AUTOSAR XML (schema 4-3-0)
standard types defined: UINT8, UINT16, UINT32, UINT64, SINT8, SINT16, SINT32, FLOAT32, FLOAT64
package /Pkg_ErrorMgrSat_2_0_B/ComponentTypes
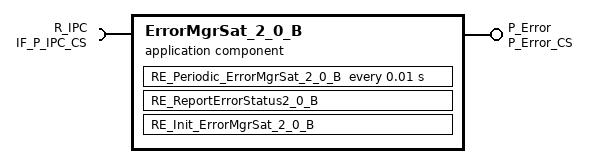
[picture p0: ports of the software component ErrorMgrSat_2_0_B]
  application sw component type ErrorMgrSat_2_0_B
    provide port P_Error: server-com-spec{operation=ReportErrorStatus2_0_B, queue-length=1}, provided-interface=P_Error_CS
    require port R_IPC: client-com-spec=IPC_Write_v, required-interface=IF_P_IPC_CS
    behavior ErrorMgrSat_2_0_B_InternalBehavior: handle-termination-and-restart=NO-SUPPORT
      timing event TMT_RE_Periodic_ErrorMgrSat_2_0_B: start-on-event=RE_Periodic_ErrorMgrSat_2_0_B, period=0.01
      operation invoked event OIT_RE_ReportErrorStatus2_0_B_P_Error_ReportErrorStatus2_0_B: start-on-event=RE_ReportErrorStatus2_0_B, operation=P_Error.ReportErrorStatus2_0_B
      init event InitEvent: start-on-event=RE_Init_ErrorMgrSat_2_0_B
      port-api-options:
        enable-take-address=false, indirect-api=false, port=P_Error
        enable-take-address=false, indirect-api=false, port=R_IPC
      runnable RE_Periodic_ErrorMgrSat_2_0_B  # Periodic Runnable of Satellite
        sync call SC_R_IPC_IPC_Write_v: operation=R_IPC.IPC_Write_v, timeout=0
      runnable RE_ReportErrorStatus2_0_B: can-be-invoked-concurrently=true  # Server Runnable for handling the error reporting
      runnable RE_Init_ErrorMgrSat_2_0_B  # Init Runnable
  swc implementation ErrorMgrSat_2_0_B_Implementation: programming-language=C, vendor-id=0, behavior=ErrorMgrSat_2_0_B_InternalBehavior
    code-descriptors:
      code Default: artifact-descriptors=autosar-engineering-object={short-label=Default, category=SWSRC}
package /Pkg_ErrorMgrSat_2_0_B/ImplementationDataTypes
  30 x impl type, all with type-emitter=RTE:
    BOOL: implementation-data-type=boolean
    ErrorMgr_ErrorField: implementation-data-type=uint8
    Error1_0QM_arr: category=ARRAY
      element Elem_ErrorMgr_ErrorField: array-size=12, array-size-semantics=FIXED-SIZE, implementation-data-type=ErrorMgr_ErrorField
    Data1_0QM_arr: category=ARRAY
      element Elem_ErrorMgr_stAddData: array-size=12, array-size-semantics=FIXED-SIZE, implementation-data-type=ErrorMgr_stAddData
    Error1_0B_arr: category=ARRAY
      element Elem_ErrorMgr_ErrorField: array-size=400, array-size-semantics=FIXED-SIZE, implementation-data-type=ErrorMgr_ErrorField
    Data1_0B_arr: category=ARRAY
      element Elem_ErrorMgr_stAddData: array-size=400, array-size-semantics=FIXED-SIZE, implementation-data-type=ErrorMgr_stAddData
    Error2_0QM_arr: category=ARRAY
      element Elem_ErrorMgr_ErrorField: array-size=1, array-size-semantics=FIXED-SIZE, implementation-data-type=ErrorMgr_ErrorField
    Padding2_0QM_arr: category=ARRAY
      element Elem_ErrorMgr_ErrorField: array-size=3, array-size-semantics=FIXED-SIZE, implementation-data-type=ErrorMgr_ErrorField
    Data2_0QM_arr: category=ARRAY
      element Elem_ErrorMgr_stAddData: array-size=1, array-size-semantics=FIXED-SIZE, implementation-data-type=ErrorMgr_stAddData
    Error2_0B_arr: category=ARRAY
      element Elem_ErrorMgr_ErrorField: array-size=144, array-size-semantics=FIXED-SIZE, implementation-data-type=ErrorMgr_ErrorField
    Data2_0B_arr: category=ARRAY
      element Elem_ErrorMgr_stAddData: array-size=144, array-size-semantics=FIXED-SIZE, implementation-data-type=ErrorMgr_stAddData
    Error2_1QM_arr: category=ARRAY
      element Elem_ErrorMgr_ErrorField: array-size=1, array-size-semantics=FIXED-SIZE, implementation-data-type=ErrorMgr_ErrorField
    Padding2_1QM_arr: category=ARRAY
      element Elem_ErrorMgr_ErrorField: array-size=3, array-size-semantics=FIXED-SIZE, implementation-data-type=ErrorMgr_ErrorField
    Data2_1QM_arr: category=ARRAY
      element Elem_ErrorMgr_stAddData: array-size=1, array-size-semantics=FIXED-SIZE, implementation-data-type=ErrorMgr_stAddData
    Error2_1B_arr: category=ARRAY
      element Elem_ErrorMgr_ErrorField: array-size=548, array-size-semantics=FIXED-SIZE, implementation-data-type=ErrorMgr_ErrorField
    Data2_1B_arr: category=ARRAY
      element Elem_ErrorMgr_stAddData: array-size=548, array-size-semantics=FIXED-SIZE, implementation-data-type=ErrorMgr_stAddData
    ErrorQNXQM_arr: category=ARRAY
      element Elem_ErrorMgr_ErrorField: array-size=1, array-size-semantics=FIXED-SIZE, implementation-data-type=ErrorMgr_ErrorField
    PaddingQNXQM_arr: category=ARRAY
      element Elem_ErrorMgr_ErrorField: array-size=3, array-size-semantics=FIXED-SIZE, implementation-data-type=ErrorMgr_ErrorField
    DataQNXQM_arr: category=ARRAY
      element Elem_ErrorMgr_stAddData: array-size=1, array-size-semantics=FIXED-SIZE, implementation-data-type=ErrorMgr_stAddData
    ErrorQNXB_arr: category=ARRAY
      element Elem_ErrorMgr_ErrorField: array-size=8, array-size-semantics=FIXED-SIZE, implementation-data-type=ErrorMgr_ErrorField
    DataQNXB_arr: category=ARRAY
      element Elem_ErrorMgr_stAddData: array-size=8, array-size-semantics=FIXED-SIZE, implementation-data-type=ErrorMgr_stAddData
    AdditionalData_arr: category=ARRAY
      element Elem_uint8: array-size=4, array-size-semantics=FIXED-SIZE, implementation-data-type=uint8
    ErrorMgr_enErrorNo: compu {12=ErrorMgr_Error_Battery_UnderVoltage, 13=ErrorMgr_Error_Battery_OverVoltage, 14=ErrorMgr_Error_Vehicle_CanBusoff_CAN2, 15=ErrorMgr_Error_Vehicle_CanBusoff_CAN14, 16=ErrorMgr_Error_MissingMessage_AGSM_FD2, 17=ErrorMgr_Error_DLC_Fault_AGSM_FD2, 18=ErrorMgr_Error_MissingMessage_BCM_FD2, 19=ErrorMgr_Error_DLC_Fault_BCM_FD2, 20=ErrorMgr_Error_MissingMessage_BCM_FD9, 21=ErrorMgr_Error_DLC_Fault_BCM_FD9, 22=ErrorMgr_Error_MissingMessage_BCM_FD10, 23=ErrorMgr_Error_DLC_Fault_BCM_FD10, 24=ErrorMgr_Error_MissingMessage_BCM_FD12, 25=ErrorMgr_Error_DLC_Fault_BCM_FD12, 26=ErrorMgr_Error_MissingMessage_BCM_FD27, 27=ErrorMgr_Error_DLC_Fault_BCM_FD27, 28=ErrorMgr_Error_MissingMessage_BCM_FD29, 29=ErrorMgr_Error_DLC_Fault_BCM_FD29, 30=ErrorMgr_Error_MissingMessage_DRIVETRAIN_FD3, 31=ErrorMgr_Error_DLC_Fault_DRIVETRAIN_FD3, 32=ErrorMgr_Error_MissingMessage_IPC_VEHICLE_SETUP, 33=ErrorMgr_Error_DLC_Fault_IPC_VEHICLE_SETUP, 34=ErrorMgr_Error_MissingMessage_IPC_FD1, 35=ErrorMgr_Error_DLC_Fault_IPC_FD1, 36=ErrorMgr_Error_MissingMessage_TRANSM_FD1, 37=ErrorMgr_Error_DLC_Fault_TRANSM_FD1, 38=ErrorMgr_Error_MissingMessage_TRANSM_FD2, 39=ErrorMgr_Error_DLC_Fault_TRANSM_FD2, 40=ErrorMgr_Error_MissingMessage_TRANSM_FD4, 41=ErrorMgr_Error_DLC_Fault_TRANSM_FD4, 42=ErrorMgr_Error_MissingMessage_ASCM_FD1, 43=ErrorMgr_Error_DLC_Fault_ASCM_FD1, 44=ErrorMgr_Error_MissingMessage_ASCM_FD2, 45=ErrorMgr_Error_DLC_Fault_ASCM_FD2, 46=ErrorMgr_Error_MissingMessage_VIN, 47=ErrorMgr_Error_DLC_Fault_VIN, 48=ErrorMgr_Error_MissingMessage_TELEMATIC_FD5, 49=ErrorMgr_Error_DLC_Fault_TELEMATIC_FD5, 50=ErrorMgr_Error_MissingMessage_TELEMATIC_FD14, 51=ErrorMgr_Error_DLC_Fault_TELEMATIC_FD14, 52=ErrorMgr_Error_MissingMessage_TELEMATIC_FD11, 53=ErrorMgr_Error_DLC_Fault_TELEMATIC_FD11, 54=ErrorMgr_Error_PROXI_Fault_Steering_RackPinion_Ratio_Incorr, 55=ErrorMgr_Error_PROXI_Fault_Tyre_Size_Incorr, 56=ErrorMgr_Error_PROXI_Fault_PAM_TunSet_Incorr, 57=ErrorMgr_Error_PROXI_Fault_VehiLineConf_Incorr, 58=ErrorMgr_Error_PROXI_Fault_WB_Incorr, 59=ErrorMgr_Error_PROXI_Fault_PAM_Config_Incorr, 60=ErrorMgr_Error_PROXI_Fault_Radio_Display_Type_Incorr, 61=ErrorMgr_Error_PROXI_CAN_Node_Incorr, 62=ErrorMgr_Error_PROXI_GearBox_Type_Incorr, 63=ErrorMgr_Error_PROXI_Model_Year_Incorr, 64=ErrorMgr_Error_PROXI_AutoPark_Sys_Incorr, 65=ErrorMgr_Error_MissingMessage_BRAKE_FD_1, 66=ErrorMgr_Error_DLC_Fault_BRAKE_FD_1, 67=ErrorMgr_Error_MissingMessage_BRAKE_FD_2, 68=ErrorMgr_Error_DLC_Fault_BRAKE_FD_2, 69=ErrorMgr_Error_MissingMessage_BRAKE_FD_3, 70=ErrorMgr_Error_DLC_Fault_BRAKE_FD_3, 71=ErrorMgr_Error_MissingMessage_BRAKE_FD_4, 72=ErrorMgr_Error_DLC_Fault_BRAKE_FD_4, 73=ErrorMgr_Error_MissingMessage_BRAKE_FD_7, 74=ErrorMgr_Error_DLC_Fault_BRAKE_FD_7, 75=ErrorMgr_Error_MissingMessage_EPS_FD_2, 76=ErrorMgr_Error_DLC_Fault_EPS_FD_2, 77=ErrorMgr_Error_MissingMessage_EPS_FD_1, 78=ErrorMgr_Error_DLC_Fault_EPS_FD_1, 79=ErrorMgr_Error_BRAKE1_REF_VEH_SPD_Invld, 80=ErrorMgr_Error_BRAKE1_VehStandStillSts_Invld, 81=ErrorMgr_Error_BRAKEFD1_ExternalBrkRequestsDisabled, 82=ErrorMgr_Error_BRAKE2_LatAcc_Invld, 83=ErrorMgr_Error_BRAKE2_LatAcc_FailSts_Invld, 84=ErrorMgr_Error_BRAKE2_LongAcc_Invld, 85=ErrorMgr_Error_BRAKE2_LongAcc_FailSts_Invld, 86=ErrorMgr_Error_BRAKE2_VehSpd_VSO_Invld, 87=ErrorMgr_Error_BRAKE2_YawRate_Invld, 88=ErrorMgr_Error_BRAKE2_YawRate_FailSts_Invld, 89=ErrorMgr_Error_BRAKE3_LatAcc_Offset_Invld, 90=ErrorMgr_Error_BRAKE3_LongAcc_Offset_Invld, 91=ErrorMgr_Error_BRAKE3_LHF_FastPulseCntr_Invld, 92=ErrorMgr_Error_BRAKE3_LHF_Spin_Invld, 93=ErrorMgr_Error_BRAKE3_LHF_WhlSenFailSts_Invld, 94=ErrorMgr_Error_BRAKE3_LHR_FastPulseCntr_Invld, 95=ErrorMgr_Error_BRAKE3_LHR_Spin_Invld, 96=ErrorMgr_Error_BRAKE3_LHR_WhlSenFailSts_Invld, 97=ErrorMgr_Error_BRAKE3_RHF_FastPulseCntr_Invld, 98=ErrorMgr_Error_BRAKE3_RHF_Spin_Invld, 99=ErrorMgr_Error_BRAKE3_RHF_WhlSenFailSts_Invld, 100=ErrorMgr_Error_BRAKE3_RHR_FastPulseCntr_Invld, 101=ErrorMgr_Error_BRAKE3_RHR_Spin_Invld, 102=ErrorMgr_Error_BRAKE3_RHR_WhlSenFailSts_Invld, 103=ErrorMgr_Error_BRAKE3_LHF_WhlSpd_Invld, 104=ErrorMgr_Error_BRAKE3_LHR_WhlSpd_Invld, 105=ErrorMgr_Error_BRAKE3_RHF_WhlSpd_Invld, 106=ErrorMgr_Error_BRAKE3_RHR_WhlSpd_Invld, 107=ErrorMgr_Error_BRAKE4_EPBSts_Invld, 108=ErrorMgr_Error_BRAKE5_BSM_THABrkResp_Invld, 109=ErrorMgr_Error_MissingMessage_BRAKE_FD_5, 110=ErrorMgr_Error_DLC_Fault_BRAKE_FD_5, 111=ErrorMgr_Error_BRAKE5_ESC_TRSCBrkResp_Invld, 112=ErrorMgr_Error_CRC_Fault_BRAKE5, 113=ErrorMgr_Error_MC_Fault_BRAKE5, 114=ErrorMgr_Error_CRC_Fault_BRAKE2, 115=ErrorMgr_Error_CRC_Fault_BRAKE3, 116=ErrorMgr_Error_CRC_Fault_BRAKE1, 117=ErrorMgr_Error_CRC_Fault_BRAKE4, 118=ErrorMgr_Error_MC_Fault_BRAKE2, 119=ErrorMgr_Error_MC_Fault_BRAKE3, 120=ErrorMgr_Error_MC_Fault_BRAKE1, 121=ErrorMgr_Error_MC_Fault_BRAKE4, 122=ErrorMgr_Error_EPS2_THA_DrivrTqOvrride_Invld, 123=ErrorMgr_Error_EPS2_THA_SteeringTqResp_Invld, 124=ErrorMgr_Error_EPS1_SPM_LAT_Ctrl_Resp_Invld, 125=ErrorMgr_Error_EPS1_LWS_Angle_Invld, 126=ErrorMgr_Error_EPS1_LWS_Spd_Invld, 127=ErrorMgr_Error_CRC_Fault_EPS2, 128=ErrorMgr_Error_MC_Fault_EPS2, 129=ErrorMgr_Error_CRC_Fault_EPS1, 130=ErrorMgr_Error_MC_Fault_EPS1, 131=ErrorMgr_Error_AGSMD_ShifrLevrPosReq_Invld, 132=ErrorMgr_Error_BCM9_Ext_Temp_Invld, 133=ErrorMgr_Error_BCM10_CmdIgnSt_Invld, 134=ErrorMgr_Error_BCM27_TrailrConnSts_Invld, 135=ErrorMgr_Error_BCM29_ITBM_TrailrStat_Invld, 136=ErrorMgr_Error_DRIVETRAIN3_TCASERANGESts_Invld, 137=ErrorMgr_Error_IPC_VEH_SETUP_LangSel_Invld, 138=ErrorMgr_Error_IPC_VEH_SETUP_PAMChmVol_F_Invld, 139=ErrorMgr_Error_IPC_VEH_SETUP_PAMChmVol_R_Invld, 140=ErrorMgr_Error_TRANSM1_TargetGear_Invld, 141=ErrorMgr_Error_TRANSM1_ADAS_Inhibit_Invld, 142=ErrorMgr_Error_TRANSM4_GearEngd_Invld, 143=ErrorMgr_Error_TRANSM4_ShiftLvrPos_Invld, 144=ErrorMgr_Error_VIN_Msg_Invld, 145=ErrorMgr_Error_ASCM1_FL_Lvl_Invld, 146=ErrorMgr_Error_ASCM1_FR_Lvl_Invld, 147=ErrorMgr_Error_ASCM1_RL_Lvl_Invld, 148=ErrorMgr_Error_ASCM1_RR_Lvl_Invld, 149=ErrorMgr_Error_ASCM2_Stat_Invld, 150=ErrorMgr_Error_ASCM2_SysFail_Fault, 151=ErrorMgr_Error_TRANSM2_GearEngdForDisp_Invld, 152=ErrorMgr_Error_CRC_Fault_BCM9, 153=ErrorMgr_Error_CRC_Fault_BCM10, 154=ErrorMgr_Error_CRC_Fault_BCM12, 155=ErrorMgr_Error_CRC_Fault_DRIVETRAIN3, 156=ErrorMgr_Error_CRC_Fault_TRANSM1, 157=ErrorMgr_Error_CRC_Fault_TRANSM2, 158=ErrorMgr_Error_CRC_Fault_TRANSM4, 159=ErrorMgr_Error_CRC_Fault_BCM27, 160=ErrorMgr_Error_CRC_Fault_BCM29, 161=ErrorMgr_Error_CRC_Fault_AGSM2, 162=ErrorMgr_Error_MC_Fault_BCM2, 163=ErrorMgr_Error_MC_Fault_BCM9, 164=ErrorMgr_Error_MC_Fault_BCM10, 165=ErrorMgr_Error_MC_Fault_BCM12, 166=ErrorMgr_Error_MC_Fault_BCM27, 167=ErrorMgr_Error_MC_Fault_BCM29, 168=ErrorMgr_Error_MC_Fault_DRIVETRAIN3, 169=ErrorMgr_Error_MC_Fault_TRANSM1, 170=ErrorMgr_Error_MC_Fault_TRANSM2, 171=ErrorMgr_Error_MC_Fault_TRANSM4, 172=ErrorMgr_Error_MC_Fault_AGSM2, 173=ErrorMgr_Error_TELEMATIC5_CM_TCH_STAT_Invld, 174=ErrorMgr_Error_TELEMATIC5_CM_TCH_X_COORD_Invld, 175=ErrorMgr_Error_TELEMATIC5_CM_TCH_Y_COORD_Invld, 176=ErrorMgr_Error_TELEMT11_HU_TRSC_EnBtnSts_Invld, 177=ErrorMgr_Error_TELEMT14_TGW_Cam_Disp_St_Invld, 178=ErrorMgr_Error_TELEMT5_CamDispSts_Invld, 179=ErrorMgr_Error_CRC_Fault_TELEMT14, 180=ErrorMgr_Error_MC_Fault_TELEMT14, 181=ErrorMgr_Error_CRC_Fault_TELEMT11, 182=ErrorMgr_Error_MC_Fault_TELEMT11, 183=ErrorMgr_Error_CRC_Fault_TELEMT5, 184=ErrorMgr_Error_MC_Fault_TELEMT5, 185=ErrorMgr_Error_BCM12_APAReqSts_Stuck_Fault, 186=ErrorMgr_Error_BCM12_PAMReqSts_Stuck_Fault, 187=ErrorMgr_Error_BCM12_FTPAMReqSts_Stuck_Fault, 188=ErrorMgr_Error_BRAKE7_PAM_BrkRqRspSts_Invld, 189=ErrorMgr_Error_CRC_Fault_BRAKE7, 190=ErrorMgr_Error_MC_Fault_BRAKE7, 191=ErrorMgr_Error_EPS1_LWS_Angle_Typ_Invld, 192=ErrorMgr_Error_CRC_Fault_BCM2, 193=ErrorMgr_Error_V_Meas_RearCam_ADC_Ctrl_OORL, 194=ErrorMgr_Error_V_Meas_RearCam_ADC_Ctrl_OORH, 195=ErrorMgr_Error_V_Meas_FrontCam_ADC_Ctrl_OORL, 196=ErrorMgr_Error_V_Meas_FrontCam_ADC_Ctrl_OORH, 197=ErrorMgr_Error_V_Meas_LeftCam_ADC_Ctrl_OORL, 198=ErrorMgr_Error_V_Meas_LeftCam_ADC_Ctrl_OORH, 199=ErrorMgr_Error_V_Meas_RightCam_ADC_Ctrl_OORL, 200=ErrorMgr_Error_V_Meas_RightCam_ADC_Ctrl_OORH, 201=ErrorMgr_Error_SVC_Cam_Calibration_Fault, 202=ErrorMgr_Error_ECU_In_Plant_Mode_Fault, 203=ErrorMgr_Error_EPS2_EPS_SteeringTqResp_Invld, 204=ErrorMgr_Error_EPS2_THA_SteerTouchStat_Invld, 205=ErrorMgr_Error_AGSM2_Shiftr_ADAS_Inhbt_Invld, 206=ErrorMgr_Error_MissingMessage_ECM_ENGINE_FD2, 207=ErrorMgr_Error_MissingMessage_ECM_ENGINE_FD5, 208=ErrorMgr_Error_MissingMessage_ECM_ENGINE_FD7, 209=ErrorMgr_Error_DLC_Fault_ECM_ENGINE_FD2, 210=ErrorMgr_Error_DLC_Fault_ECM_ENGINE_FD5, 211=ErrorMgr_Error_DLC_Fault_ECM_ENGINE_FD7, 212=ErrorMgr_Error_Engine2_EngineSts_W_ECM_Invld, 213=ErrorMgr_Error_Engine_FD_5_ECM_PdlPosActual, 214=ErrorMgr_Error_Engine_FD_7_ECM_TRSC_Resp_Invld, 215=ErrorMgr_Error_Engine_FD_7_ECM_THA_Resp_Invld, 216=ErrorMgr_Error_ECM_CRC_Fault_ENGINE2, 217=ErrorMgr_Error_ECM_MC_Fault_ENGINE2, 218=ErrorMgr_Error_ECM_CRC_Fault_ENGINE7, 219=ErrorMgr_Error_ECM_MC_Fault_ENGINE7, 220=ErrorMgr_Error_SVC_Rear_Incorrect_Device_ID_Fault, 221=ErrorMgr_Error_SVC_Front_Incorrect_Device_ID_Fault, 222=ErrorMgr_Error_SVC_Left_Incorrect_Device_ID_Fault, 223=ErrorMgr_Error_SVC_Right_Incorrect_Device_ID_Fault, 224=ErrorMgr_Error_SysIntFlt_MCU_MSPI_E2E_Protect_Fail, 225=ErrorMgr_Error_SysIntFlt_MCU_ADC_uncorrectable_ECC, 226=ErrorMgr_Error_SysIntFlt_MCU_ADC_Memory_Violation, 227=ErrorMgr_Error_SysIntFlt_MCU_ADC_Input_Failure, 228=ErrorMgr_Error_SysIntFlt_Main_UDMA_Configuration_register_mismatch, 229=ErrorMgr_Error_SysIntFlt_Main_UDMA_E2E_protection_failure, 230=ErrorMgr_Error_SysIntFlt_Main_UDMA_Uncorrectable_ECC_error, 231=ErrorMgr_Error_SysIntFlt_MCU_CRC_Failure_in_Safety_critical_data_primary_copy, 232=ErrorMgr_Error_SysIntFlt_MCU_CRC_Failure_in_Safety_critical_data_second_copy, 233=ErrorMgr_Error_SysIntFlt_MCU_CRC_Failure_in_Safety_critical_data_primary_second_copy, 234=ErrorMgr_Error_SysIntFlt_MCU_WD_RST_INT, 235=ErrorMgr_Error_SysIntFlt_MCU_PMIC_WD_FAIL_CNT, 236=ErrorMgr_Error_SysIntFlt_MCU_SM7_ILIM_Reached_Threshold, 237=ErrorMgr_Error_SysIntFlt_MCU_SM8_Thermal_prewarning_Interrupt, 238=ErrorMgr_Error_SysIntFlt_MCU_SM12_Redundant_Readback_Error_GPIO_Pin_nRSTOUT_SoC_Pin, 239=ErrorMgr_Error_SysIntFlt_MCU_SM17_CRC_Error_I2C1_Channel, 240=ErrorMgr_Error_SysIntFlt_MCU_SM22_Notify_Host_Previously_Detected_Errors, 241=ErrorMgr_Error_SysIntFlt_MCU_SM4_UV_OV_threshold_reached_in_slave_MCU_Rail_group, 242=ErrorMgr_Error_SysIntFlt_MCU_SM7_ILIM_Reached_Threshold_Slave, 243=ErrorMgr_Error_SysIntFlt_MCU_SM8_Thermal_prewarning_Interrupt_Slave, 244=ErrorMgr_Error_SysIntFlt_MCU_SM17_CRC_Error_I2C1_Channel_Slave, 245=ErrorMgr_Error_SysIntFlt_MCU_SM22_Notify_Host_Previously_Detected_Errors_Slave, 246=ErrorMgr_Error_SysIntFlt_MCU_SM7_ILIM_Reached_Threshold_HERA, 247=ErrorMgr_Error_SysIntFlt_MCU_SM8_Thermal_prewarning_Interrupt_HERA, 248=ErrorMgr_Error_SysIntFlt_MCU_SM17_CRC_Error_I2C1_Channel_HERA, 249=ErrorMgr_Error_SysIntFlt_MCU_SM22_Notify_Host_Previously_Detected_Errors_HERA, 250=ErrorMgr_Error_SysIntFlt_Main_DDRSS0_DDRSS_registers_readback_error, 251=ErrorMgr_Error_SysIntFlt_Main_DDRSS0_Parity_check_failure_in_DDRSS, 252=ErrorMgr_Error_SysIntFlt_Main_DDRSS0_Two_BIT_and_multibit_ECC_Failure_in_DDR_data, 253=ErrorMgr_Error_SysIntFlt_MCU_CBASS_Mismatch_registers, 254=ErrorMgr_Error_SysIntFlt_Main_CBASS_Mismatch_registers, 255=ErrorMgr_Error_SysIntFlt_MCU_CBASS_Parity_failure_of_override_registers, 256=ErrorMgr_Error_SysIntFlt_Main_CBASS_Parity_failure_of_override_registers, 257=ErrorMgr_Error_SysIntFlt_MCU_Clock_Loss_input_detected, 258=ErrorMgr_Error_SysIntFlt_MCU_Clock_reference_error, 259=ErrorMgr_Error_SysIntFlt_Main_Domain_clock_reference_error, 260=ErrorMgr_Error_SysIntFlt_MCU_Clock_failure_detected_safety_relevant_peripheral_clock, 261=ErrorMgr_Error_SysIntFlt_Main_Clock_failure_detected_safety_relevant_peripheral_clock, 262=ErrorMgr_Error_SysIntFlt_MCU_Clock_PLL_slip_detected, 263=ErrorMgr_Error_SysIntFlt_Main_Clock_PLL_slip_detected, 264=ErrorMgr_Error_SysIntFlt_Main_Configuration_registers_of_CLK_CTRL_and_PLL_readback_error, 265=ErrorMgr_Error_SysIntFlt_MCU_PWR_Supply_Internal_POK_monitoring_VDD_CORE, 266=ErrorMgr_Error_SysIntFlt_Main_PWR_Supply_Internal_POK_monitoring_VDD_CPU, 267=ErrorMgr_Error_SysIntFlt_DMSC_LBIST_error, 268=ErrorMgr_Error_SysIntFlt_DMSC_ECC_failure_SMS_SRAM, 269=ErrorMgr_Error_SysIntFlt_DMSC_PBIST_failure_for_memory_space, 270=ErrorMgr_Error_SysIntFlt_MCU_ESM_Memory_violation_WKUP_ESM0_configuration_registers, 271=ErrorMgr_Error_SysIntFlt_MCU_ESM_Memory_violation_MCU_ESM0_configuration_registers, 272=ErrorMgr_Error_SysIntFlt_Main_ESM_Mismatich_ESM0_configuration_registers, 273=ErrorMgr_Error_SysIntFlt_MCU_ESM_WKUP_I2C0_E2E_protection_failure, 274=ErrorMgr_Error_SysIntFlt_MCU_ESM_I2C_E2E_protection_failure, 275=ErrorMgr_Error_SysIntFlt_MCU_ESM_Memory_violation_in_WKUP_I2C_and_MCU_I2C_configuration_registers, 276=ErrorMgr_Error_SysIntFlt_MCU_Reset_POST_failure, 277=ErrorMgr_Error_SysIntFlt_MCU_Reset_Reset_Configuration_registers_error, 278=ErrorMgr_Error_SysIntFlt_MCU_R5F_Failure_reported_Lockstep_core, 279=ErrorMgr_Error_SysIntFlt_MCU_R5F_LBIST_error, 280=ErrorMgr_Error_SysIntFlt_MCU_R5F_MPU_Violation_in_R5F_Domain_Core, 281=ErrorMgr_Error_SysIntFlt_MCU_R5F_Illegal_operations_and_instructions_R5F, 282=ErrorMgr_Error_SysIntFlt_MCU_R5F_CPU_Configuration_registers_readback_error, 283=ErrorMgr_Error_SysIntFlt_MCU_R5F_ECC_failure_R5F_memory, 284=ErrorMgr_Error_SysIntFlt_MCU_R5F_PBIST_check_MemError_Internal_RAMCache_and_Config_registers, 285=ErrorMgr_Error_SysIntFlt_Main_R5F_PBIST_check_MemError_Internal_RAMCache_and_Config_registers, 286=ErrorMgr_Error_SysIntFlt_MCU_R5F_Fault_inject_Test_Failure_on_Memory_ECC, 287=ErrorMgr_Error_SysIntFlt_MCU_R5F_Fault_inject_Test_Failur_on_MPU_functionality, 288=ErrorMgr_Error_SysIntFlt_MCU_R5F_Fault_inject_test_failure_on_illegal_operation_and_instruction, 289=ErrorMgr_Error_SysIntFlt_MCU_R5F_Fault_inject_Test_Failure_on_Lockstep_Compare, 290=ErrorMgr_Error_SysIntFlt_Main_R5F_Program_sequence_error, 291=ErrorMgr_Error_SysIntFlt_Main_R5F_LBIST_error, 292=ErrorMgr_Error_SysIntFlt_Main_R5F_CPU_Configuration_registers_readback_error, 293=ErrorMgr_Error_SysIntFlt_Main_R5F_R5F_Memory_violation, 294=ErrorMgr_Error_SysIntFlt_Main_R5F_ECC_failure_R5F_memory, 295=ErrorMgr_Error_SysIntFlt_Main_R5F_Fault_inject_Test_Failur_on_MPU_functionality, 296=ErrorMgr_Error_SysIntFlt_Main_R5F_Fault_inject_test_failure_on_illegal_operation_and_instruction, 297=ErrorMgr_Error_SysIntFlt_MCU_MSRAM_Uncorrectable_ECC_error, 298=ErrorMgr_Error_SysIntFlt_Main_MSRAM_Uncorrectable_ECC_error, 299=ErrorMgr_Error_SysIntFlt_MCU_MSRAM_Fault_inject_failure_ECC, 300=ErrorMgr_Error_SysIntFlt_Main_MSRAM_Fault_inject_failure_ECC, 301=ErrorMgr_Error_SysIntFlt_MCU_MSRAM_PBIST_error, 302=ErrorMgr_Error_SysIntFlt_Main_MSRAM_PBIST_error, 303=ErrorMgr_Error_SysIntFlt_MCU_MMR_MCUCtrl_WKUPCtrl_Mismatch, 304=ErrorMgr_Error_SysIntFlt_MCU_MMR_MPU_MemViolation, 305=ErrorMgr_Error_SysIntFlt_MCU_MMR_1_Bit_MCUCtrl_WKUPCtrl_Register_Err, 306=ErrorMgr_Error_SysIntFlt_MCU_MMR_Parity_Failure, 307=ErrorMgr_Error_SysIntFlt_Main_MMR_ParityErr_FaultInjection, 308=ErrorMgr_Error_SysIntFlt_Main_MMR_CTRL_MMR0_Mismatch, 309=ErrorMgr_Error_SysIntFlt_Main_VTM_OverTemp_Interrupt, 310=ErrorMgr_Error_SysIntFlt_Main_VTM_Registers_Mismatch, 311=ErrorMgr_Error_SysIntFlt_MCU_GPIO_ConfigReg_Mismatch, 312=ErrorMgr_Error_SysIntFlt_Main_GPIO_Memory_Violation, 313=ErrorMgr_Error_SysIntFlt_Main_GPIO_Config_Mismatch, 314=ErrorMgr_Error_SysIntFlt_Main_MSMC_Ctrl_Address_Sig_ParityErr, 315=ErrorMgr_Error_SysIntFlt_MCU_MSMC_ECC_Err, 316=ErrorMgr_Error_SysIntFlt_Main_MSMC_Config_Register_Mismatch, 317=ErrorMgr_Error_SysIntFlt_Main_MSMC_ECC_MSMCParityErr_FaultInjection, 318=ErrorMgr_Error_SysIntFlt_Main_MSMC_ECC_Err_in_MSMCIntrcnnct, 319=ErrorMgr_Error_SysIntFlt_Main_MSMC_CtrlSig_MSMCIntrcnnct_Chache_Err, 320=ErrorMgr_Error_SysIntFlt_Main_MSMC_ECC_Err_in_MSMC_Cache_Tag_Memory, 321=ErrorMgr_Error_SysIntFlt_Main_MSMC_ECC_Err_SRAMTagData_SRAMData, 322=ErrorMgr_Error_SysIntFlt_Main_MSMC_Lvl3_Cache_Snoop_On_Chip_SRAM_ParityErr, 323=ErrorMgr_Error_SysIntFlt_Main_MSMC_SRAM_PBIST_Check_Fail, 324=ErrorMgr_Error_SysIntFlt_Main_MSMC_Memory_Violation, 325=ErrorMgr_Error_SysIntFlt_MCU_NAVSS_FaultInjection_Routing_Interrupt_Err, 326=ErrorMgr_Error_SysIntFlt_MCU_NAVSS_NAVSS_Interrupt_Router_Mismatch, 327=ErrorMgr_Error_SysIntFlt_Main_NAVSS_Interrupt_FaultInjection_Err, 328=ErrorMgr_Error_SysInrnlFlt_Main_NAVSS_InterruptRouter_Registers_Mismatch, 329=ErrorMgr_Error_SysIntFlt_Main_NAVSSInterruptAggregator_Mismatch, 330=ErrorMgr_Error_SysIntFlt_Main_NAVSS_IA_MemSpace_ECC_Err, 331=ErrorMgr_Error_SysIntFlt_Main_NAVSS_FaultInjection_IA_Config_Register_ECC_Err, 332=ErrorMgr_Error_SysIntFlt_Main_NAVSS_PBIST_Check_Fail, 333=ErrorMgr_Error_SysIntFlt_Main_NAVSS_IA_1Bit_Parity_Err, 334=ErrorMgr_Error_SysIntFlt_Main_NAVSS_Poll_SourceRegisters_Interrupts_Err, 335=ErrorMgr_Error_SysIntFlt_MCU_NAVSS_Registers_Mismatch, 336=ErrorMgr_Error_SysIntFlt_MCU_NAVSS_NAVSS_IA_Mem_ECC_Err, 337=ErrorMgr_Error_SysIntFlt_MCU_NAVSS_FaultInjection_ECC_Err, 338=ErrorMgr_Error_SysIntFlt_MCU_NAVSS_PBIST_Check_Fail, 339=ErrorMgr_Error_SysIntFlt_MCU_NAVSS_1Bit_Parity_Err, 340=ErrorMgr_Error_SysIntFlt_MCU_NAVSS_SourceRegister_Interrupts_Polling_Err, 341=ErrorMgr_Error_SysIntFlt_MCU_NAVSS_FaultInjection_ParityCheck_Err, 342=ErrorMgr_Error_SysIntFlt_Main_NAVSSMailbox_Memory_ECC_Err, 343=ErrorMgr_Error_SysIntFlt_Main_NAVSSMailbox_FaultInjection_ECC_Err, 344=ErrorMgr_Error_SysIntFlt_Main_NAVSSMailbox_1Bit_ParityCheck_Err, 345=ErrorMgr_Error_SysIntFlt_Main_NAVSSMailbox_FaultInjection_ParityCheck_Err, 346=ErrorMgr_Error_SysIntFlt_Main_NAVSSMailbox_PBIST_Memory_Err, 347=ErrorMgr_Error_SysIntFlt_MCU_Timer_2TimerSyncCheck, 348=ErrorMgr_Error_SysIntFlt_MCU_Timer_SW_Test_Fail, 349=ErrorMgr_Error_SysIntFlt_Main_Timer_2TimerSyncCheck_MainDomain, 350=ErrorMgr_Error_SysIntFlt_Main_Timer_Memory_Violation, 351=ErrorMgr_Error_SysIntFlt_Main_Timer_StartUpSWTest_Timer, 352=ErrorMgr_Error_SysIntFlt_MCU_Timer_ESMErrInterrupt_Timeout, 353=ErrorMgr_Error_SysIntFlt_MCU_VIM_ECC_Err, 354=ErrorMgr_Error_SysIntFlt_MCU_VIM_Register_Config_Mismatch, 355=ErrorMgr_Error_SysIntFlt_MCU_VIM_PBIST_MemoryCheck_Fail, 356=ErrorMgr_Error_SysIntFlt_MCU_VIM_FaultInjection_ECC_Err, 357=ErrorMgr_Error_SysIntFlt_Main_VIM_ECC_Err, 358=ErrorMgr_Error_SysIntFlt_Main_VIM_PBIST_MemoryCheck_Err, 359=ErrorMgr_Error_SysIntFlt_Main_VIM_FaultInjection_ECC_err, 360=ErrorMgr_Error_SysIntFlt_Main_VBUSM_ESM_error_interrupt_IP_hung, 361=ErrorMgr_Error_SysIntFlt_MCU_VBUSM_parity_protection_Single_bit_error, 362=ErrorMgr_Error_SysIntFlt_MCU_VBUSM_Configuration_mismatch_timeout, 363=ErrorMgr_Error_SysIntFlt_MCU_VBUSM_PBIST_memory_Failure, 364=ErrorMgr_Error_SysIntFlt_MCU_VBUSM_Parity_detection_Error, 365=ErrorMgr_Error_SysIntFlt_MCU_VBUSM_Uncorrectable_ECC_Error, 366=ErrorMgr_Error_SysIntFlt_Main_A72_alive_supervision_error, 367=ErrorMgr_Error_SysIntFlt_MCU_A72__configuration_Error, 368=ErrorMgr_Error_SysIntFlt_MCU_A72_Ucorrectable_ECC_Error, 369=ErrorMgr_Error_SysIntFlt_Main_ePWM_Functionality_error, 370=ErrorMgr_Error_SysIntFlt_MCU_GIC_ECC_Failure, 371=ErrorMgr_Error_SysIntFlt_MCU_ADC_Self_test_failure, 372=ErrorMgr_Error_SysIntFlt_MCU_ADC_PBIST_error, 373=ErrorMgr_Error_SysIntFlt_MCU_ADC_ECC_error, 374=ErrorMgr_Error_SysIntFlt_Main_NAVSS_Memory_Violation, 375=ErrorMgr_Error_SysIntFlt_Main_NAVSS_Functionality_Error, 376=ErrorMgr_Error_SysIntFlt_MCU_FFI_Memory_Violation, 377=ErrorMgr_Error_SysIntFlt_Main_FFI_Memory_Violation, 378=ErrorMgr_Error_SysIntFlt_MCU_FFI_Main_core_MCU_core_Communication__E2E_Protection_error, 379=ErrorMgr_Error_SysIntFlt_MCU_FFI_Main_intra_core_Communication_E2E_Protection_error, 380=ErrorMgr_Error_SysIntFlt_R1_2_0__FFI_Exec_Timing_error, 381=ErrorMgr_Error_SysIntFlt_MCU_UDMA_Memory_violation_error, 382=ErrorMgr_Error_SysIntFlt_Main_UDMA_peripheral_inject_error, 383=ErrorMgr_Error_SysIntFlt_Main_Fault_inject_failure_ECC, 384=ErrorMgr_Error_SysIntFlt_Main_UDMA_PBIST_error, 385=ErrorMgr_Error_SysIntFlt_Main_UDMA_Fault_inject_failure_ECC, 386=ErrorMgr_Error_SysIntFlt_Main_UDMA_ESM_error_invalid_range, 387=ErrorMgr_Error_SysIntFlt_Main_NAVSS_RA_PROXY_ECC_error, 388=ErrorMgr_Error_SysIntFlt_Main_NAVSS_RA_PROXY_configuration_register_runtime_error, 389=ErrorMgr_Error_SysIntFlt_Main_NAVSS_RA_PROXY_peripheral_inject_error, 390=ErrorMgr_Error_SysIntFlt_Main_NAVSS_RA_PROXY_Fault_inject_failure_ECC, 391=ErrorMgr_Error_SysIntFlt_Main_NAVSS_RA_PROXY_PBIST_error, 392=ErrorMgr_Error_SysIntFlt_Main_NAVSS_RA_PROXY_Memory_violation_error, 393=ErrorMgr_Error_SysIntFlt_MCU_A72_alive_supervision_error, 394=ErrorMgr_Error_SysIntFlt_MCU_A72_configuration_register_mismatch, 395=ErrorMgr_Error_SysIntFlt_MCU_A72_ECC_uncorrectable_error, 396=ErrorMgr_Error_SysIntFlt_MCU_A72_MMU_error, 397=ErrorMgr_Error_SysIntFlt_MCU_A72_stack_overflow_underflow_error, 398=ErrorMgr_Error_SysIntFlt_MCU_A72_heart_beat_signal_not_recieved, 399=ErrorMgr_Error_SysIntFlt_MCU_GPU_safety_critical_registers_mismatch, 400=ErrorMgr_Error_SysIntFlt_MCU_GPU_stitching_time_out_error, 401=ErrorMgr_Error_SysIntFlt_WDG_Health_Monitoring_Failure_2_1_Main_Domain, 402=ErrorMgr_Error_SysIntFlt_WDG_Health_Monitoring_Failure_2_0_Main_Domain, 403=ErrorMgr_Error_SysIntFlt_WDG_Health_Monitoring_Failure_1_0_MCU_Domain, 404=ErrorMgr_Error_SysIntFlt_WDG_Health_Monitoring_Failure_1_0_MPU_Domain, 405=ErrorMgr_Error_SysIntFlt_MCU_SM4_UV_OV_threshold_reached_in_Master_MCU_Rail_group, 406=ErrorMgr_Error_SysIntFlt_MCU_SM4_UV_OV_threshold_reached_in_HERA_MCU_Rail_group, 407=ErrorMgr_Error_SysIntFlt_MCU_TRSCCalib_CRC_Error, 408=ErrorMgr_Error_SysIntFlt_MCU_THACalib_CRC_Error, 409=ErrorMgr_Error_SysIntFlt_MCU_FODCalib_CRC_Error, 410=ErrorMgr_Error_SysIntFlt_MCU_SVSCalib_CRC_Error, 411=ErrorMgr_Error_SysIntFlt_MCU_APACalib_CRC_Error, 1112=ErrorMgr_ErrorNum_Max}, implementation-data-type=uint32
    ErrorMgr_enSafeStates: compu {0=ErrorMgr_SafeState_safestate1, 1=ErrorMgr_SafeState_safestate16, 2=ErrorMgr_SafeState_safestate23, 3=ErrorMgr_SafeState_safestate24, 4=ErrorMgr_SafeState_safestate17, 5=ErrorMgr_SafeState_safestate13, 6=ErrorMgr_SafeState_safestate12, 7=ErrorMgr_SafeState_safestate9, 8=ErrorMgr_SafeState_safestate10, 9=ErrorMgr_SafeState_safestate7, 10=ErrorMgr_SafeState_safestate4, 11=ErrorMgr_SafeState_safestate2, 12=ErrorMgr_SafeState_safestate5, 13=ErrorMgr_SafeState_safestate11, 14=ErrorMgr_SafeState_safestate21, 15=ErrorMgr_SafeState_Max}, implementation-data-type=uint32
    ErrorMgr_enErrorStatus: compu {0=ErrorMgr_Invalid, 1=ErrorMgr_ErrorInactive, 2=ErrorMgr_ErrorActive}, implementation-data-type=uint32
    ErrorMgr_ErrorCommPack_1_0_B: category=STRUCTURE
      4 x element, all with category=TYPE_REFERENCE:
        RunningCounter: implementation-data-type=uint32
        Checksum: implementation-data-type=uint32
        Error: implementation-data-type=Error1_0B_arr
        Data: implementation-data-type=Data1_0B_arr
    ErrorMgr_ErrorCommPack_2_0_B: category=STRUCTURE
      4 x element, all with category=TYPE_REFERENCE:
        RunningCounter: implementation-data-type=uint32
        Checksum: implementation-data-type=uint32
        Error: implementation-data-type=Error2_0B_arr
        Data: implementation-data-type=Data2_0B_arr
    ErrorMgr_ErrorCommPack_2_1_B: category=STRUCTURE
      4 x element, all with category=TYPE_REFERENCE:
        RunningCounter: implementation-data-type=uint32
        Checksum: implementation-data-type=uint32
        Error: implementation-data-type=Error2_1B_arr
        Data: implementation-data-type=Data2_1B_arr
    ErrorMgr_ErrorCommPack_QNX_B: category=STRUCTURE
      4 x element, all with category=TYPE_REFERENCE:
        RunningCounter: implementation-data-type=uint32
        Checksum: implementation-data-type=uint32
        Error: implementation-data-type=ErrorQNXB_arr
        Data: implementation-data-type=DataQNXB_arr
    ErrorMgr_stAddData: category=STRUCTURE
      element AdditionalData: implementation-data-type=AdditionalData_arr
package /Pkg_ErrorMgrSat_2_0_B/PortInterfaces
  client server interface P_Error_CS
    operation ReportErrorStatus2_0_B: possible-error=E_NOK
      arg err: type=ErrorMgr_enErrorNo, direction=IN, server-argument-impl-policy=USE-ARGUMENT-TYPE
      arg errStatus: type=ErrorMgr_enErrorStatus, direction=IN, server-argument-impl-policy=USE-ARGUMENT-TYPE
      arg addData: type=ErrorMgr_stAddData, direction=IN, server-argument-impl-policy=USE-ARGUMENT-TYPE
    error E_NOK: error-code=1
